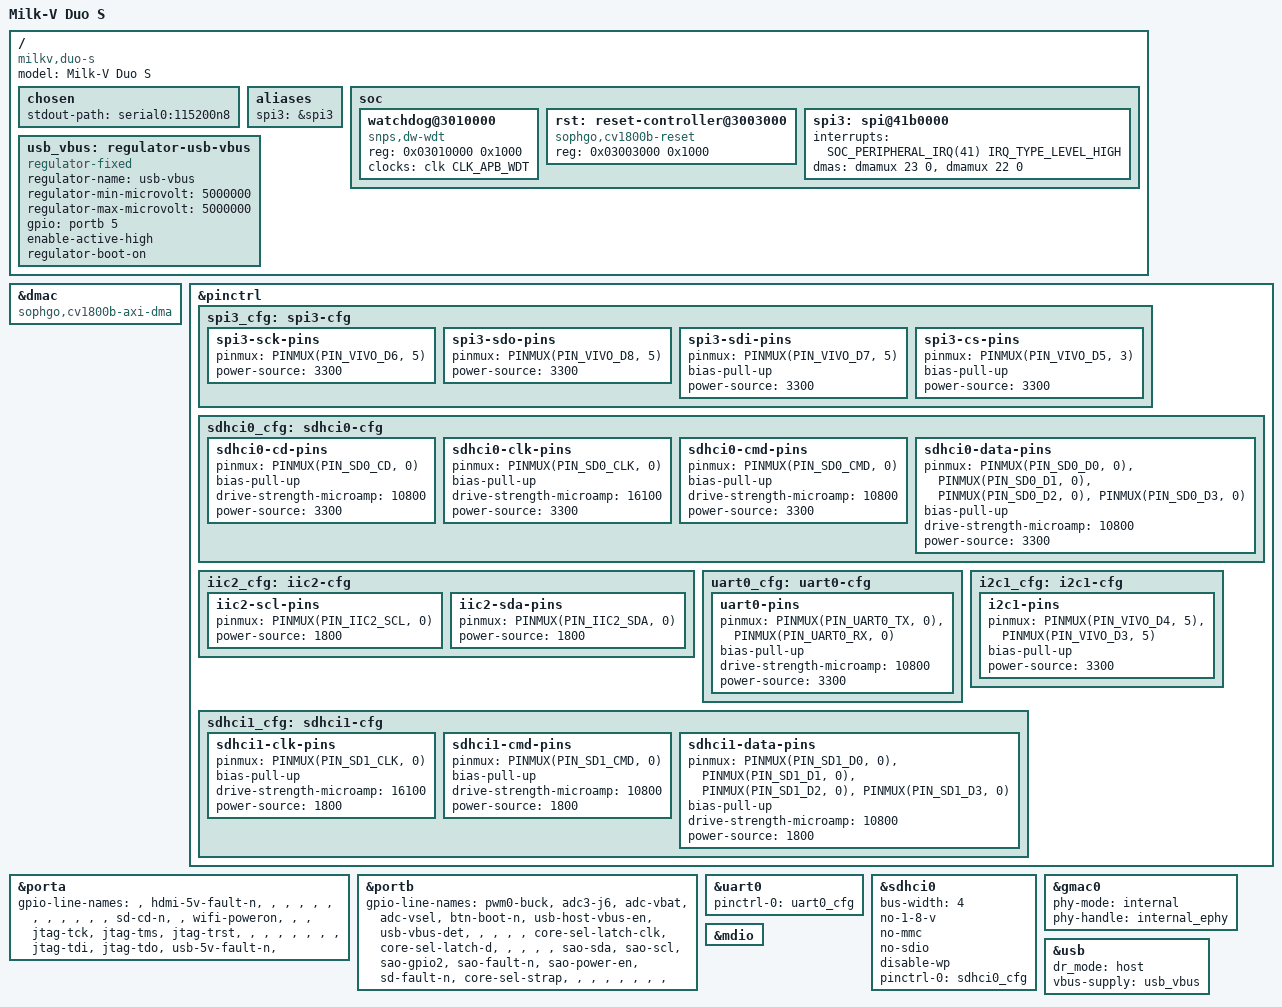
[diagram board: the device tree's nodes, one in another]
// SPDX-License-Identifier: (GPL-2.0 OR MIT)
/*
 * Device tree for the Milk-V Duo S (Sophgo SG2000, aarch64 ARM Cortex-A53).
 *
 * Based on mainline sg2000-milkv-duo-module-01-evb.dts.
 *
 * The Duo S uses the SG2000 SoM (Module 01) with a carrier board. This DTS
 * reuses the Module 01 DTSI, which enables eMMC, the sdhci1/WiFi stubs, and
 * aliases. It then adds the nodes that the Duo S carrier contributes:
 *   - uart0, enabled.
 *   - sdhci0, enabled for the SD card root.
 *   - chosen stdout-path for the ttyS0 console.
 *   - Ethernet: SG2000 internal EPHY (phy-mode = "internal"). The carrier has
 *     no external PHY. The DTSI sets phy-handle=<&internal_ephy> and
 *     phy-mode="internal". This DTS enables the MAC and MDIO.
 *   - USB: the usb node, enabled with dr_mode = "host". The carrier exposes a
 *     USB-A host port. GPIO portb pin 5 (USB_VBUS_EN) gates the port VBUS.
 *
 * Carrier nodes that are omitted:
 *   - LEDs and GPIO buttons: carrier-specific, not in the mainline sg2000 DTSI.
 *   - Camera/CSI: the ISP nodes are not in the mainline sg2000 DTSI.
 */

/dts-v1/;
#include "sg2000-milkv-duo-module-01.dtsi"
#include <dt-bindings/gpio/gpio.h>
#include "sg2000-milkv-duo-s-common.dtsi"

/ {
	model = "Milk-V Duo S";
	compatible = "milkv,duo-s", "sophgo,sg2000";

	chosen {
		stdout-path = "serial0:115200n8";
	};
};

/*
 * SoC reset for userspace `reboot`.
 *
 * The mainline sg2000.dtsi has no watchdog node, so mainline Linux registers
 * no restart handler for this SoC other than PSCI. The inherited /psci node
 * (arm,psci-0.2, method "smc") routes machine_restart to SYSTEM_RESET in BL31.
 * The SG2000 BL31 blob does not implement SYSTEM_RESET. The SMC returns and
 * machine_restart() spins forever after printing "reboot: Restarting system".
 *
 * The fix is to expose the CV1800B/SG2000 Synopsys DesignWare watchdog. The
 * mainline dw_wdt driver (CONFIG_DW_WDT) registers a restart handler at
 * priority 128. Its dw_wdt_restart() programs the shortest timeout in RESET
 * response mode and kicks the counter. This asserts the SoC watchdog-reset line.
 *
 * The watchdog reset output is gated in the always-on RTC block by
 * RTC_EN_WDT_RST_REQ (0x050260E0). The vendor FSBL (sophgo/fsbl plat/cv181x,
 * built by pkgs/firmware/fsbl.nix) writes 0x050260E0 = 1 in early platform
 * init. A watchdog timeout then propagates to a full SoC reset. Mainline Linux
 * does not clear that bit, so the watchdog restart handler resets the SoC.
 *
 * Node facts:
 *   - base 0x03010000, size 0x1000: from the vendor cv181x_base.dtsi
 *     "cv-wd@0x3010000" (compatible "snps,dw-wdt") and vendor u-boot
 *     WATCHDOG_BASE = TOP_BASE + 0x10000 = 0x03000000 + 0x10000.
 *   - clock CLK_APB_WDT (58): the mainline sophgo clk driver registers the
 *     clk_apb_wdt gate off the 25 MHz osc, matching the vendor
 *     CONFIG_DW_WDT_CLOCK_KHZ 25000. dw_wdt takes the first unnamed clock
 *     (devm_clk_get_enabled(dev, NULL)) as its timer clock.
 * `resets` is omitted. dw_wdt treats it as optional and the WDT is already out
 * of reset from u-boot. This avoids a dependency on the sophgo,cv1800b-reset
 * driver being built in.
 */
/* The mainline sg2000.dtsi gives the soc node no label, so merge by full path. */
/ {
	/* The SPI core sets bus_num from of_alias_get_id(node, "spi") and falls
	 * back to dynamic numbering when no alias matches. This alias fixes the
	 * controller to bus 3, so the device is /dev/spidev3.0 and not
	 * /dev/spidev0.0. */
	aliases {
		spi3 = &spi3;
	};

	soc {
		watchdog@3010000 {
			compatible = "snps,dw-wdt";
			reg = <0x03010000 0x1000>;
			clocks = <&clk CLK_APB_WDT>;
		};

		/* Reset controller. reset-simple handles sophgo,cv1800b-reset. The
		 * mainline sg2000.dtsi omits it. SPI3 comes up held in reset on the
		 * ARM core, so its register access stalls the dw_spi probe until the
		 * driver deasserts RST_SPI3. */
		rst: reset-controller@3003000 {
			compatible = "sophgo,cv1800b-reset";
			reg = <0x03003000 0x1000>;
			#reset-cells = <1>;
		};

		/* SPI3 (DesignWare APB SSI) drives the WS2812 ring + Sharp panel. The
		 * controller (compatible/reg/clocks/resets) is inherited from the base
		 * cv180x.dtsi; the shared device config (num-cs, cs-gpios, pinctrl,
		 * spidev@0, display@1, status) lives in the common dtsi. This node carries
		 * only the arm-specific bits:
		 *   - interrupts: the GIC 3-cell form (the base's 2-cell PLIC form is wrong
		 *     under the arm64 GIC), so override it here.
		 *   - dmas: cv1800b dmamux slave DMA so the CPU no longer hand-refills the
		 *     TX FIFO (PIO underruns when a hardirq preempts the refill and the
		 *     WS2812 chain glitches under load). Cells: TX req 23, RX req 22; 2nd
		 *     cell = CPU (0 = CA53). &dmac must be sophgo,cv1800b-axi-dma
		 *     (ARG0_AS_CHAN). RST_SPI3 (base `resets`) needs RESET_SIMPLE, enabled
		 *     in the shared base.nix. */
		spi3: spi@41b0000 {
			interrupts = <SOC_PERIPHERAL_IRQ(41) IRQ_TYPE_LEVEL_HIGH>;
			dmas = <&dmamux 23 0>, <&dmamux 22 0>;
			dma-names = "tx", "rx";
		};
	};
};

/*
 * DMA controller for SPI3 slave DMA (see the &spi3 dmas above). The base
 * cv180x.dtsi gives it the generic snps,axi-dma-1.01a compatible, which lacks
 * ARG0_AS_CHAN, so dw_axi_dma_of_xlate would take the apb_regs handshake path
 * this SoC never wires up ("apb_regs not initialized"). sophgo,cv1800b-axi-dma
 * sets ARG0_AS_CHAN, so of_xlate uses the channel the dmamux allocated. The
 * dmamux (dma-router@154) lives in the always-on top syscon and is already live.
 */
&dmac {
	compatible = "sophgo,cv1800b-axi-dma";
	status = "okay";
};

/*
 * Pin configuration for the SD0 and UART0 pads. The pinmux matches the EVB
 * carrier.
 */
&pinctrl {
	/* SPI3 on the 40-pin header (pads VIVO_D5..D8, mux 5). The VIVO pads are
	 * 3.3V on the carrier, so power-source = <3300>. power-source is required:
	 * the mainline sophgo pinctrl (cv1800_dt_node_to_map_post) returns -EINVAL
	 * for any pinmux subnode that omits it. That fails pinctrl_bind_pins in
	 * really_probe before dw_spi_mmio_probe runs (silent EINVAL, no dev_err). */
	spi3_cfg: spi3-cfg {
		/* No bias-disable. The mainline sophgo pinctrl (sophgo_pconf_set)
		 * supports pull-up, pull-down, and bus-hold, but not BIAS_DISABLE,
		 * and returns -ENOTSUPP for it. That failure rolls back the whole
		 * pinctrl state, including the mux, and leaves the pins unclaimed.
		 * Omitting bias leaves the pad at its default (no pull), which suits
		 * a push-pull SCK/MOSI. */
		spi3-sck-pins {
			pinmux = <PINMUX(PIN_VIVO_D6, 5)>;
			power-source = <3300>;
		};
		spi3-sdo-pins {
			pinmux = <PINMUX(PIN_VIVO_D8, 5)>;
			power-source = <3300>;
		};
		spi3-sdi-pins {
			pinmux = <PINMUX(PIN_VIVO_D7, 5)>;
			bias-pull-up;
			power-source = <3300>;
		};
		/* CS is a GPIO here, not SPI3_CS. Mux 3 is XGPIOB_16; mux 5
		 * would be SPI3_CS. The board gates LED_DIN with CS through the
		 * U10 AND gate and needs it active high, which the native DW CS
		 * cannot do. See the cs-gpios comment on &spi3. */
		spi3-cs-pins {
			pinmux = <PINMUX(PIN_VIVO_D5, 3)>;
			bias-pull-up;
			power-source = <3300>;
		};
	};

	sdhci0_cfg: sdhci0-cfg {
		sdhci0-cd-pins {
			pinmux = <PINMUX(PIN_SD0_CD, 0)>;
			bias-pull-up;
			drive-strength-microamp = <10800>;
			power-source = <3300>;
		};

		sdhci0-clk-pins {
			pinmux = <PINMUX(PIN_SD0_CLK, 0)>;
			bias-pull-up;
			drive-strength-microamp = <16100>;
			power-source = <3300>;
		};

		sdhci0-cmd-pins {
			pinmux = <PINMUX(PIN_SD0_CMD, 0)>;
			bias-pull-up;
			drive-strength-microamp = <10800>;
			power-source = <3300>;
		};

		sdhci0-data-pins {
			pinmux = <PINMUX(PIN_SD0_D0, 0)>,
				 <PINMUX(PIN_SD0_D1, 0)>,
				 <PINMUX(PIN_SD0_D2, 0)>,
				 <PINMUX(PIN_SD0_D3, 0)>;
			bias-pull-up;
			drive-strength-microamp = <10800>;
			power-source = <3300>;
		};
	};

	/* IIC2, the LT8912B control bus: pads PIN_IIC2_SCL/SDA (balls J13/J14,
	 * module pins 39/40, net I2C_SENSOR1). IIC2 is their primary function, so
	 * mux 0 (pinctrl-sg2000.c: CV1800_GENERAL_PIN(PIN_IIC2_*)).
	 *
	 * power-source = <1800>, not 3300: the pads are IO_TYPE_1V8_ONLY in the
	 * VDDIO_RTC domain. The sophgo pinctrl keeps one power-cfg per domain and
	 * returns -EINVAL (unclaiming the whole group) when a later pin in the
	 * same domain disagrees; every VDDIO_RTC pad in the SG2000 table is
	 * 1V8-only, so every group muxed there must say 1800.
	 *
	 * No bias: I2C is open-drain with external 10 k pull-ups, and the sophgo
	 * pinctrl rejects bias-disable (-ENOTSUPP), as for the spi3 sck/sdo pins. */
	iic2_cfg: iic2-cfg {
		iic2-scl-pins {
			pinmux = <PINMUX(PIN_IIC2_SCL, 0)>;
			power-source = <1800>;
		};
		iic2-sda-pins {
			pinmux = <PINMUX(PIN_IIC2_SDA, 0)>;
			power-source = <1800>;
		};
	};

	uart0_cfg: uart0-cfg {
		uart0-pins {
			pinmux = <PINMUX(PIN_UART0_TX, 0)>,
				 <PINMUX(PIN_UART0_RX, 0)>;
			bias-pull-up;
			drive-strength-microamp = <10800>;
			power-source = <3300>;
		};
	};

	/* SAO connector IIC1 for the SSD1306 OLED (see &i2c1 in the common dtsi).
	 * The SAO SDA/SCL are PORTB 17/18 = pads VIVO_D4 / VIVO_D3, IIC1 = pinmux 5
	 * (found empirically: mux 5 is the only value where 0x3c ACKs). bias-pull-up
	 * both enables the pad input buffer (so the controller senses SDA/the ACK --
	 * without it the mux is set but reads NAK) and adds an internal pull that
	 * parallels the U12 TXS0104E's. power-source is required by the mainline
	 * sophgo pinctrl or it -EINVALs the whole state (see spi3_cfg). */
	i2c1_cfg: i2c1-cfg {
		i2c1-pins {
			pinmux = <PINMUX(PIN_VIVO_D4, 5)>, /* SAO SDA, portb 17 */
				 <PINMUX(PIN_VIVO_D3, 5)>; /* SAO SCL, portb 18 */
			bias-pull-up;
			power-source = <3300>;
		};
	};
};

/*
 * GPIO line names, so gpioinfo reads as a wiring diagram instead of a list of
 * numbers.
 *
 * Names only. This sets no direction, no pull, and no pad mux, so it cannot
 * change board behaviour. Every consumer still claims its own line.
 *
 * porta and portb are XGPIOA and XGPIOB. The board also uses a porte
 * (PWR_GPIO, the RTC domain block at 0x05021000) for the USER button and the
 * HDMI I2C pads. Mainline has no such controller node and pinctrl-sg2000.h
 * names only PWR_GPIO0..2, so those lines are not representable here.
 */
&porta {
	gpio-line-names =
		"",                  /* 0  CAM_MCLK0 (pin 12, NC) */
		"hdmi-5v-fault-n",   /* 1  U19 /FAULT */
		"", "", "", "", "", "",
		"", "",
		"",                  /* 10 SD_D1 */
		"", "",
		"sd-cd-n",           /* 13 SD card detect */
		"",
		"wifi-poweron",      /* 15 on-module AIC8800 */
		"",                  /* 16 UART0_TX */
		"",
		"jtag-tck",          /* 18 */
		"jtag-tms",          /* 19 */
		"jtag-trst",         /* 20 */
		"", "", "", "", "", "", "",
		"jtag-tdi",          /* 28 v1A datasheet swaps TDI/TDO */
		"jtag-tdo",          /* 29 */
		"usb-5v-fault-n",    /* 30 U5 /FAULT */
		"";
};

&portb {
	gpio-line-names =
		"pwm0-buck",         /* 0 */
		"adc3-j6",           /* 1  SARADC ch3 */
		"adc-vbat",          /* 2  SARADC ch2 */
		"adc-vsel",          /* 3  SARADC ch1 */
		"btn-boot-n",        /* 4  S1, also the ROM recovery strap */
		"usb-host-vbus-en",  /* 5  wired-AND with SERIAL_VBUS */
		"usb-vbus-det",      /* 6 */
		"", "", "", "",
		"core-sel-latch-clk",/* 11 U2 74AUP1G175 CP */
		"core-sel-latch-d",  /* 12 1=ARM, 0=RISC-V on next boot */
		"",                  /* 13 SPI3_SDO, LED chain via U10 */
		"",                  /* 14 SPI3_SDI */
		"",                  /* 15 SPI3_SCK */
		"",                  /* 16 SPI3_CS, gates LED_DIN via U10 */
		"sao-sda",           /* 17 IIC1 through U12 TXS0104E */
		"sao-scl",           /* 18 IIC1 */
		"sao-gpio2",         /* 19 */
		"sao-fault-n",       /* 20 U13 /FAULT */
		"sao-power-en",      /* 21 U13 EN + U12 OE */
		"sd-fault-n",        /* 22 U8 /FAULT */
		"core-sel-strap",    /* 23 readback: 1=RISC-V, 0=ARM */
		"", "", "", "", "", "", "", "";
};

/* Console UART */
&uart0 {
	pinctrl-0 = <&uart0_cfg>;
	pinctrl-names = "default";
	status = "okay";
};

/* SD card (rootfs on /dev/mmcblk0, NIXOS_ARM label) */
&sdhci0 {
	bus-width = <4>;
	no-1-8-v;
	no-mmc;
	no-sdio;
	disable-wp;
	pinctrl-0 = <&sdhci0_cfg>;
	pinctrl-names = "default";
	status = "okay";
};

/* On-chip 10/100 Ethernet: SG2000 internal EPHY straight to the RJ45 magnetics.
 * The carrier has no external PHY. phy-mode is set to "internal" with the
 * internal EPHY handle. Note: mainline 7.0.x has no driver to power or init the
 * internal EPHY (no cv1800b dwmac glue, no EPHY phy driver), so eth0 registers
 * but does not link until the EPHY is initialized (for example in U-Boot) or a
 * kernel driver lands. */
&gmac0 {
	status = "okay";
	phy-mode = "internal";
	phy-handle = <&internal_ephy>;
};

&mdio {
	status = "okay";
};

/*
 * USB: SG2000 DWC2 OTG core driving the USB-A host port.
 * dr_mode is "host". The carrier exposes a USB-A host port.
 * VBUS to the port is gated by USB_VBUS_EN = GPIO portb pin 5, modelled as a
 * fixed regulator so the port powers bus-powered devices.
 */
/ {
	usb_vbus: regulator-usb-vbus {
		compatible = "regulator-fixed";
		regulator-name = "usb-vbus";
		regulator-min-microvolt = <5000000>;
		regulator-max-microvolt = <5000000>;
		gpio = <&portb 5 GPIO_ACTIVE_HIGH>;
		enable-active-high;
		regulator-boot-on;
	};
};

&usb {
	dr_mode = "host";
	vbus-supply = <&usb_vbus>;
	status = "okay";
};

/*
 * WiFi SDIO bus pads. The mmc@4320000 controller uses the SD1 pads
 * (PIN_SD1_*, mux 0 = SDIO1, the same scheme as the SD0 pads for the card).
 * Without this mux the pads stay on their default function and the AIC8800
 * does not answer the SDIO probe.
 */
&pinctrl {
	/* The AIC8800 SDIO IO (VIO) is fixed 1.8V on this board, so the SoC SD1
	 * pads must be in the 1.8V IO domain, not 3.3V. With power-source=3300 the
	 * pad domain mismatches the chip's 1.8V VIO, and the fmac firmware's
	 * higher-rate SDIO fails to confirm START_APP. Set 1800 to match.
	 */
	sdhci1_cfg: sdhci1-cfg {
		sdhci1-clk-pins {
			pinmux = <PINMUX(PIN_SD1_CLK, 0)>;
			bias-pull-up;
			drive-strength-microamp = <16100>;
			power-source = <1800>;
		};

		sdhci1-cmd-pins {
			pinmux = <PINMUX(PIN_SD1_CMD, 0)>;
			bias-pull-up;
			drive-strength-microamp = <10800>;
			power-source = <1800>;
		};

		sdhci1-data-pins {
			pinmux = <PINMUX(PIN_SD1_D0, 0)>,
				 <PINMUX(PIN_SD1_D1, 0)>,
				 <PINMUX(PIN_SD1_D2, 0)>,
				 <PINMUX(PIN_SD1_D3, 0)>;
			bias-pull-up;
			drive-strength-microamp = <10800>;
			power-source = <1800>;
		};
	};
};
